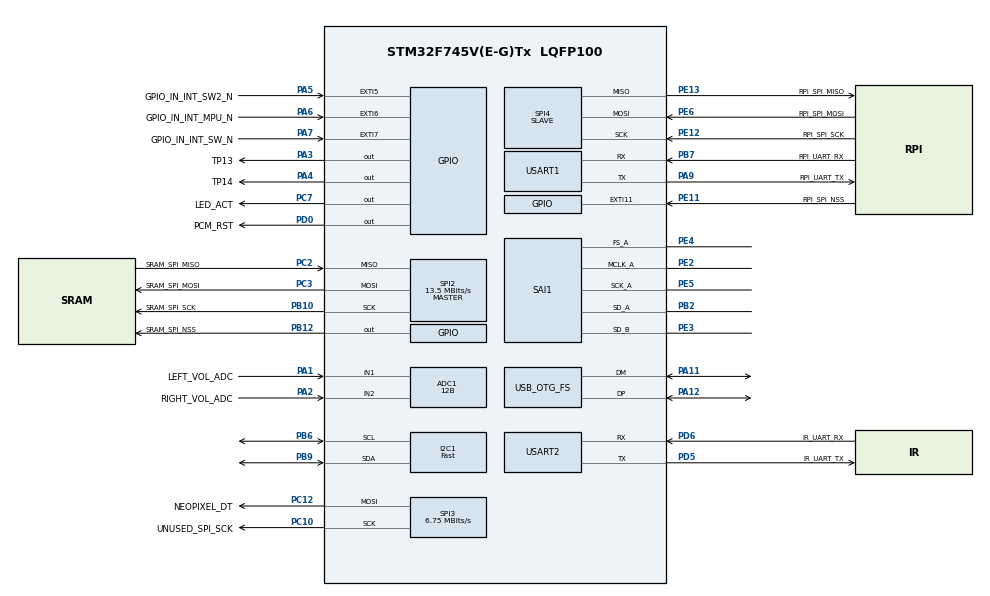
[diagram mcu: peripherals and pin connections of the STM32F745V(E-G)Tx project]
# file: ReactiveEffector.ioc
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ADC1.Channel-0\#ChannelRegularConversion=ADC_CHANNEL_1
ADC1.Channel-9\#ChannelRegularConversion=ADC_CHANNEL_2
ADC1.ClockPrescaler=ADC_CLOCK_SYNC_PCLK_DIV8
ADC1.ContinuousConvMode=ENABLE
ADC1.DMAContinuousRequests=ENABLE
ADC1.EOCSelection=ADC_EOC_SINGLE_CONV
ADC1.InjNumberOfConversion=0
ADC1.NbrOfConversion=2
ADC1.NbrOfConversionFlag=1
ADC1.Rank-0\#ChannelRegularConversion=1
ADC1.Rank-9\#ChannelRegularConversion=2
ADC1.Resolution=ADC_RESOLUTION_12B
ADC1.SamplingTime-0\#ChannelRegularConversion=ADC_SAMPLETIME_480CYCLES
ADC1.SamplingTime-9\#ChannelRegularConversion=ADC_SAMPLETIME_480CYCLES
ADC1.ScanConvMode=ADC_SCAN_ENABLE
ADC1.master=1
CORTEX_M7.ART_ACCLERATOR_ENABLE=0
CORTEX_M7.CPU_DCache=Enabled
CORTEX_M7.CPU_ICache=Enabled
CORTEX_M7.PREFETCH_ENABLE=0
CRC.InputDataFormat=CRC_INPUTDATA_FORMAT_WORDS
Dma.ADC1.11.Direction=DMA_PERIPH_TO_MEMORY
Dma.ADC1.11.FIFOMode=DMA_FIFOMODE_DISABLE
Dma.ADC1.11.Instance=DMA2_Stream4
Dma.ADC1.11.MemDataAlignment=DMA_MDATAALIGN_HALFWORD
Dma.ADC1.11.MemInc=DMA_MINC_ENABLE
Dma.ADC1.11.Mode=DMA_CIRCULAR
Dma.ADC1.11.PeriphDataAlignment=DMA_PDATAALIGN_HALFWORD
Dma.ADC1.11.PeriphInc=DMA_PINC_DISABLE
Dma.ADC1.11.Priority=DMA_PRIORITY_LOW
Dma.I2C1_RX.8.Direction=DMA_PERIPH_TO_MEMORY
Dma.I2C1_RX.8.FIFOMode=DMA_FIFOMODE_DISABLE
Dma.I2C1_RX.8.Instance=DMA1_Stream0
Dma.I2C1_RX.8.MemDataAlignment=DMA_MDATAALIGN_BYTE
Dma.I2C1_RX.8.MemInc=DMA_MINC_ENABLE
Dma.I2C1_RX.8.Mode=DMA_NORMAL
Dma.I2C1_RX.8.PeriphDataAlignment=DMA_PDATAALIGN_BYTE
Dma.I2C1_RX.8.PeriphInc=DMA_PINC_DISABLE
Dma.I2C1_RX.8.Priority=DMA_PRIORITY_LOW
Dma.I2C1_TX.5.Direction=DMA_MEMORY_TO_PERIPH
Dma.I2C1_TX.5.FIFOMode=DMA_FIFOMODE_DISABLE
Dma.I2C1_TX.5.Instance=DMA1_Stream7
Dma.I2C1_TX.5.MemDataAlignment=DMA_MDATAALIGN_BYTE
Dma.I2C1_TX.5.MemInc=DMA_MINC_ENABLE
Dma.I2C1_TX.5.Mode=DMA_NORMAL
Dma.I2C1_TX.5.PeriphDataAlignment=DMA_PDATAALIGN_BYTE
Dma.I2C1_TX.5.PeriphInc=DMA_PINC_DISABLE
Dma.I2C1_TX.5.Priority=DMA_PRIORITY_LOW
Dma.Request0=USART1_TX
Dma.Request1=SPI3_TX
Dma.Request10=SAI1_B
Dma.Request11=ADC1
Dma.Request2=USART2_TX
Dma.Request3=SPI4_RX
Dma.Request4=SPI4_TX
Dma.Request5=I2C1_TX
Dma.Request6=SPI2_RX
Dma.Request7=SPI2_TX
Dma.Request8=I2C1_RX
Dma.Request9=SAI1_A
Dma.SAI1_A.9.Direction=DMA_PERIPH_TO_MEMORY
Dma.SAI1_A.9.FIFOMode=DMA_FIFOMODE_DISABLE
Dma.SAI1_A.9.Instance=DMA2_Stream3
Dma.SAI1_A.9.MemDataAlignment=DMA_MDATAALIGN_WORD
Dma.SAI1_A.9.MemInc=DMA_MINC_ENABLE
Dma.SAI1_A.9.Mode=DMA_CIRCULAR
Dma.SAI1_A.9.PeriphDataAlignment=DMA_PDATAALIGN_WORD
Dma.SAI1_A.9.PeriphInc=DMA_PINC_DISABLE
Dma.SAI1_A.9.Priority=DMA_PRIORITY_LOW
Dma.SAI1_B.10.Direction=DMA_MEMORY_TO_PERIPH
Dma.SAI1_B.10.FIFOMode=DMA_FIFOMODE_DISABLE
Dma.SAI1_B.10.Instance=DMA2_Stream5
Dma.SAI1_B.10.MemDataAlignment=DMA_MDATAALIGN_WORD
Dma.SAI1_B.10.MemInc=DMA_MINC_ENABLE
Dma.SAI1_B.10.Mode=DMA_CIRCULAR
Dma.SAI1_B.10.PeriphDataAlignment=DMA_PDATAALIGN_WORD
Dma.SAI1_B.10.PeriphInc=DMA_PINC_DISABLE
Dma.SAI1_B.10.Priority=DMA_PRIORITY_LOW
Dma.SPI2_RX.6.Direction=DMA_PERIPH_TO_MEMORY
Dma.SPI2_RX.6.FIFOMode=DMA_FIFOMODE_DISABLE
Dma.SPI2_RX.6.Instance=DMA1_Stream3
Dma.SPI2_RX.6.MemDataAlignment=DMA_MDATAALIGN_BYTE
Dma.SPI2_RX.6.MemInc=DMA_MINC_ENABLE
Dma.SPI2_RX.6.Mode=DMA_NORMAL
Dma.SPI2_RX.6.PeriphDataAlignment=DMA_PDATAALIGN_BYTE
Dma.SPI2_RX.6.PeriphInc=DMA_PINC_DISABLE
Dma.SPI2_RX.6.Priority=DMA_PRIORITY_LOW
Dma.SPI2_TX.7.Direction=DMA_MEMORY_TO_PERIPH
Dma.SPI2_TX.7.FIFOMode=DMA_FIFOMODE_DISABLE
Dma.SPI2_TX.7.Instance=DMA1_Stream4
Dma.SPI2_TX.7.MemDataAlignment=DMA_MDATAALIGN_BYTE
Dma.SPI2_TX.7.MemInc=DMA_MINC_ENABLE
Dma.SPI2_TX.7.Mode=DMA_NORMAL
Dma.SPI2_TX.7.PeriphDataAlignment=DMA_PDATAALIGN_BYTE
Dma.SPI2_TX.7.PeriphInc=DMA_PINC_DISABLE
Dma.SPI2_TX.7.Priority=DMA_PRIORITY_LOW
Dma.SPI3_TX.1.Direction=DMA_MEMORY_TO_PERIPH
Dma.SPI3_TX.1.FIFOMode=DMA_FIFOMODE_DISABLE
Dma.SPI3_TX.1.Instance=DMA1_Stream5
Dma.SPI3_TX.1.MemDataAlignment=DMA_MDATAALIGN_HALFWORD
Dma.SPI3_TX.1.MemInc=DMA_MINC_ENABLE
Dma.SPI3_TX.1.Mode=DMA_NORMAL
Dma.SPI3_TX.1.PeriphDataAlignment=DMA_PDATAALIGN_HALFWORD
Dma.SPI3_TX.1.PeriphInc=DMA_PINC_DISABLE
Dma.SPI3_TX.1.Priority=DMA_PRIORITY_LOW
Dma.SPI4_RX.3.Direction=DMA_PERIPH_TO_MEMORY
Dma.SPI4_RX.3.FIFOMode=DMA_FIFOMODE_DISABLE
Dma.SPI4_RX.3.Instance=DMA2_Stream0
Dma.SPI4_RX.3.MemDataAlignment=DMA_MDATAALIGN_HALFWORD
Dma.SPI4_RX.3.MemInc=DMA_MINC_ENABLE
Dma.SPI4_RX.3.Mode=DMA_NORMAL
Dma.SPI4_RX.3.PeriphDataAlignment=DMA_PDATAALIGN_HALFWORD
Dma.SPI4_RX.3.PeriphInc=DMA_PINC_DISABLE
Dma.SPI4_RX.3.Priority=DMA_PRIORITY_LOW
Dma.SPI4_TX.4.Direction=DMA_MEMORY_TO_PERIPH
Dma.SPI4_TX.4.FIFOMode=DMA_FIFOMODE_DISABLE
Dma.SPI4_TX.4.Instance=DMA2_Stream1
Dma.SPI4_TX.4.MemDataAlignment=DMA_MDATAALIGN_HALFWORD
Dma.SPI4_TX.4.MemInc=DMA_MINC_ENABLE
Dma.SPI4_TX.4.Mode=DMA_NORMAL
Dma.SPI4_TX.4.PeriphDataAlignment=DMA_PDATAALIGN_HALFWORD
Dma.SPI4_TX.4.PeriphInc=DMA_PINC_DISABLE
Dma.SPI4_TX.4.Priority=DMA_PRIORITY_LOW
Dma.USART1_TX.0.Direction=DMA_MEMORY_TO_PERIPH
Dma.USART1_TX.0.FIFOMode=DMA_FIFOMODE_DISABLE
Dma.USART1_TX.0.Instance=DMA2_Stream7
Dma.USART1_TX.0.MemDataAlignment=DMA_MDATAALIGN_BYTE
Dma.USART1_TX.0.MemInc=DMA_MINC_ENABLE
Dma.USART1_TX.0.Mode=DMA_NORMAL
Dma.USART1_TX.0.PeriphDataAlignment=DMA_PDATAALIGN_BYTE
Dma.USART1_TX.0.PeriphInc=DMA_PINC_DISABLE
Dma.USART1_TX.0.Priority=DMA_PRIORITY_LOW
Dma.USART2_TX.2.Direction=DMA_MEMORY_TO_PERIPH
Dma.USART2_TX.2.FIFOMode=DMA_FIFOMODE_DISABLE
Dma.USART2_TX.2.Instance=DMA1_Stream6
Dma.USART2_TX.2.MemDataAlignment=DMA_MDATAALIGN_BYTE
Dma.USART2_TX.2.MemInc=DMA_MINC_ENABLE
Dma.USART2_TX.2.Mode=DMA_NORMAL
Dma.USART2_TX.2.PeriphDataAlignment=DMA_PDATAALIGN_BYTE
Dma.USART2_TX.2.PeriphInc=DMA_PINC_DISABLE
Dma.USART2_TX.2.Priority=DMA_PRIORITY_LOW
FREERTOS.HEAP_NUMBER=1
FREERTOS.Tasks01=usbTxTask,1,128,usbTxTaskProc,As weak,NULL,Dynamic,NULL,NULL;i2cTask,2,256,i2cTaskProc,As external,NULL,Dynamic,NULL,NULL;neoPixelTask,-3,128,neoPixelTaskProc,As external,NULL,Dynamic,NULL,NULL;appTask,-3,256,appTaskProc,As external,NULL,Dynamic,NULL,NULL;soundTask,3,256,soundTaskProc,As external,NULL,Dynamic,NULL,NULL;adcTask,-3,128,adcTaskProc,As external,NULL,Dynamic,NULL,NULL
FREERTOS.configENABLE_FPU=1
FREERTOS.configTOTAL_HEAP_SIZE=289000
FREERTOS.configUSE_NEWLIB_REENTRANT=1
FREERTOS.configUSE_TIMERS=0
I2C1.I2C_Fall_Time=50
I2C1.I2C_Rise_Time=50
I2C1.I2C_Speed_Mode=I2C_Fast
I2C1.Timing=0x00802F47
Mcu.Family=STM32F7
Mcu.Name=STM32F745V(E-G)Tx
Mcu.Package=LQFP100
Mcu.UserConstants=SRAM_SPI,SPI2;NP_SPI,SPI3;RPI_SPI,SPI4;RPI_UART,USART1;IR_UART,USART2
NVIC.DMA1_Stream0_IRQn=true\:5\:0\:false\:false\:false\:true\:false\:true\:true
NVIC.DMA1_Stream3_IRQn=true\:5\:0\:false\:false\:false\:true\:false\:true\:true
NVIC.DMA1_Stream4_IRQn=true\:5\:0\:false\:false\:false\:true\:false\:true\:true
NVIC.DMA1_Stream5_IRQn=true\:5\:0\:false\:false\:false\:true\:false\:true\:true
NVIC.DMA1_Stream6_IRQn=true\:5\:0\:false\:false\:false\:true\:false\:true\:true
NVIC.DMA1_Stream7_IRQn=true\:5\:0\:false\:false\:false\:true\:false\:true\:true
NVIC.DMA2_Stream0_IRQn=true\:5\:0\:false\:false\:false\:true\:false\:true\:true
NVIC.DMA2_Stream1_IRQn=true\:5\:0\:false\:false\:false\:true\:false\:true\:true
NVIC.DMA2_Stream3_IRQn=true\:5\:0\:false\:false\:false\:true\:false\:true\:true
NVIC.DMA2_Stream4_IRQn=true\:5\:0\:false\:false\:false\:true\:false\:true\:true
NVIC.DMA2_Stream5_IRQn=true\:5\:0\:false\:false\:false\:true\:false\:true\:true
NVIC.DMA2_Stream7_IRQn=true\:5\:0\:false\:false\:false\:true\:false\:true\:true
NVIC.EXTI15_10_IRQn=true\:5\:0\:false\:false\:false\:true\:true\:true\:true
NVIC.EXTI9_5_IRQn=true\:5\:0\:false\:false\:false\:true\:true\:true\:true
NVIC.I2C1_ER_IRQn=true\:5\:0\:false\:false\:false\:true\:true\:true\:true
NVIC.I2C1_EV_IRQn=true\:5\:0\:false\:false\:false\:true\:true\:true\:true
NVIC.OTG_FS_IRQn=true\:5\:0\:false\:false\:false\:true\:false\:true\:true
NVIC.PriorityGroup=NVIC_PRIORITYGROUP_4
NVIC.TIM1_UP_TIM10_IRQn=true\:5\:0\:false\:false\:false\:true\:true\:true\:true
NVIC.TIM6_DAC_IRQn=true\:5\:0\:false\:false\:false\:true\:true\:true\:true
NVIC.TIM7_IRQn=true\:0\:0\:false\:false\:false\:false\:false\:true\:true
NVIC.TimeBase=TIM7_IRQn
NVIC.TimeBaseIP=TIM7
NVIC.USART1_IRQn=true\:5\:0\:false\:false\:false\:true\:true\:true\:true
NVIC.USART2_IRQn=true\:5\:0\:false\:false\:false\:true\:true\:true\:true
PA1.GPIO_Label=LEFT_VOL_ADC
PA1.Signal=ADCx_IN1
PA10.Signal=USB_OTG_FS_ID
PA11.Mode=Device_Only
PA11.Signal=USB_OTG_FS_DM
PA12.Mode=Device_Only
PA12.Signal=USB_OTG_FS_DP
PA13.Mode=JTAG_5_pins
PA13.Signal=SYS_JTMS-SWDIO
PA14.Mode=JTAG_5_pins
PA14.Signal=SYS_JTCK-SWCLK
PA15.Mode=JTAG_5_pins
PA15.Signal=SYS_JTDI
PA2.GPIO_Label=RIGHT_VOL_ADC
PA2.Signal=ADCx_IN2
PA3.GPIO_Label=TP13
PA3.Signal=GPIO_Output
PA4.GPIO_Label=TP14
PA4.Signal=GPIO_Output
PA5.GPIO_Label=GPIO_IN_INT_SW2_N
PA5.GPIO_ModeDefaultEXTI=GPIO_MODE_IT_FALLING
PA5.GPIO_PuPd=GPIO_PULLUP
PA5.Signal=GPXTI5
PA6.GPIO_Label=GPIO_IN_INT_MPU_N
PA6.GPIO_ModeDefaultEXTI=GPIO_MODE_IT_FALLING
PA6.GPIO_PuPd=GPIO_PULLUP
PA6.Signal=GPXTI6
PA7.GPIO_Label=GPIO_IN_INT_SW_N
PA7.GPIO_ModeDefaultEXTI=GPIO_MODE_IT_FALLING
PA7.GPIO_PuPd=GPIO_PULLUP
PA7.Signal=GPXTI7
PA9.GPIO_Label=RPI_UART_TX
PA9.Mode=Asynchronous
PA9.Signal=USART1_TX
PB10.GPIO_Label=SRAM_SPI_SCK
PB10.Mode=Full_Duplex_Master
PB10.Signal=SPI2_SCK
PB12.GPIO_Label=SRAM_SPI_NSS
PB12.Signal=GPIO_Output
PB2.Mode=SAI_A_MasterWithClock
PB2.Signal=SAI1_SD_A
PB3.Mode=JTAG_5_pins
PB3.Signal=SYS_JTDO-SWO
PB4.Mode=JTAG_5_pins
PB4.Signal=SYS_JTRST
PB6.GPIO_Pu=GPIO_PULLUP
PB6.Mode=I2C
PB6.Signal=I2C1_SCL
PB7.GPIO_Label=RPI_UART_RX
PB7.Mode=Asynchronous
PB7.Signal=USART1_RX
PB9.GPIO_Pu=GPIO_PULLUP
PB9.Mode=I2C
PB9.Signal=I2C1_SDA
PC1.Mode=SYS_WakeUp2
PC1.Signal=SYS_WKUP3
PC10.GPIO_Label=UNUSED_SPI_SCK
PC10.Mode=TX_Only_Simplex_Unidirect_Master
PC10.Signal=SPI3_SCK
PC12.GPIO_Label=NEOPIXEL_DT
PC12.Mode=TX_Only_Simplex_Unidirect_Master
PC12.Signal=SPI3_MOSI
PC2.GPIO_Label=SRAM_SPI_MISO
PC2.Mode=Full_Duplex_Master
PC2.Signal=SPI2_MISO
PC3.GPIO_Label=SRAM_SPI_MOSI
PC3.Mode=Full_Duplex_Master
PC3.Signal=SPI2_MOSI
PC7.GPIO_Label=LED_ACT
PC7.Signal=GPIO_Output
PD0.GPIO_Label=PCM_RST
PD0.Signal=GPIO_Output
PD5.GPIO_Label=IR_UART_TX
PD5.Mode=Asynchronous
PD5.Signal=USART2_TX
PD6.GPIO_Label=IR_UART_RX
PD6.Mode=Asynchronous
PD6.Signal=USART2_RX
PE11.GPIO_Label=RPI_SPI_NSS
PE11.GPIO_ModeDefaultEXTI=GPIO_MODE_IT_FALLING
PE11.Signal=GPXTI11
PE12.GPIO_Label=RPI_SPI_SCK
PE12.Mode=Full_Duplex_Slave
PE12.Signal=SPI4_SCK
PE13.GPIO_Label=RPI_SPI_MISO
PE13.Mode=Full_Duplex_Slave
PE13.Signal=SPI4_MISO
PE2.Mode=SAI_A_MasterWithClock
PE2.Signal=SAI1_MCLK_A
PE3.Mode=SAI_B_SyncSlave
PE3.Signal=SAI1_SD_B
PE4.Mode=SAI_A_MasterWithClock
PE4.Signal=SAI1_FS_A
PE5.Mode=SAI_A_MasterWithClock
PE5.Signal=SAI1_SCK_A
PE6.GPIO_Label=RPI_SPI_MOSI
PE6.Mode=Full_Duplex_Slave
PE6.Signal=SPI4_MOSI
PH0/OSC_IN.Mode=HSE-External-Oscillator
PH0/OSC_IN.Signal=RCC_OSC_IN
PH1/OSC_OUT.Mode=HSE-External-Oscillator
PH1/OSC_OUT.Signal=RCC_OSC_OUT
ProjectManager.HeapSize=0x200
ProjectManager.StackSize=0x1000
ProjectManager.TargetToolchain=STM32CubeIDE
RCC.AHBFreq_Value=216000000
RCC.APB1CLKDivider=RCC_HCLK_DIV4
RCC.APB1Freq_Value=54000000
RCC.APB1TimFreq_Value=108000000
RCC.APB2CLKDivider=RCC_HCLK_DIV2
RCC.APB2Freq_Value=108000000
RCC.APB2TimFreq_Value=216000000
RCC.CortexFreq_Value=216000000
RCC.HCLKFreq_Value=216000000
RCC.HSE_VALUE=8000000
RCC.HSI_VALUE=16000000
RCC.LSE_VALUE=32768
RCC.PLLI2SN=216
RCC.PLLM=4
RCC.PLLN=216
RCC.PLLQ=9
RCC.PLLSAIN=182
RCC.SYSCLKFreq_VALUE=216000000
RCC.SYSCLKSource=RCC_SYSCLKSOURCE_PLLCLK
RCC.USBFreq_Value=48000000
RCC.VCOOutputFreq_Value=432000000
SAI1.AudioFrequency-SAI_A_MasterWithClock=SAI_AUDIO_FREQUENCY_44K
SAI1.AudioMode-SAI_A_MasterWithClock=SAI_MODEMASTER_RX
SAI1.AudioMode-SAI_B_SyncSlave=SAI_MODESLAVE_TX
SAI1.BasicDataSize-SAI_A_MasterWithClock=SAI_PROTOCOL_DATASIZE_32BIT
SAI1.BasicDataSize-SAI_B_SyncSlave=SAI_PROTOCOL_DATASIZE_32BIT
SAI1.ErrorAudioFreq-SAI_A_MasterWithClock=0.98 %
SAI1.FIFOThreshold-SAI_B_SyncSlave=SAI_FIFOTHRESHOLD_HF
SAI1.InitProtocol-SAI_A_MasterWithClock=Enable
SAI1.InitProtocol-SAI_B_SyncSlave=Enable
SAI1.Instance-SAI_A_MasterWithClock=SAI$Index_Block_A
SAI1.Instance-SAI_B_SyncSlave=SAI$Index_Block_B
SAI1.MClockEnable=SAI_MASTERCLOCK_ENABLE
SAI1.RealAudioFreq-SAI_A_MasterWithClock=44.433 KHz
SAI1.VirtualMode-SAI_A_MasterWithClock=VM_MASTER
SAI1.VirtualMode-SAI_B_SyncSlave=VM_SLAVE
SAI1.VirtualProtocol-SAI_A_BASIC=VM_BASIC_PROTOCOL
SAI1.VirtualProtocol-SAI_B_BASIC=VM_BASIC_PROTOCOL
SH.ADCx_IN1.0=ADC1_IN1,IN1
SH.ADCx_IN2.0=ADC1_IN2,IN2
SPI2.BaudRatePrescaler=SPI_BAUDRATEPRESCALER_4
SPI2.CLKPhase=SPI_PHASE_2EDGE
SPI2.CLKPolarity=SPI_POLARITY_HIGH
SPI2.CalculateBaudRate=13.5 MBits/s
SPI2.DataSize=SPI_DATASIZE_8BIT
SPI2.Direction=SPI_DIRECTION_2LINES
SPI2.Mode=SPI_MODE_MASTER
SPI2.VirtualType=VM_MASTER
SPI3.BaudRatePrescaler=SPI_BAUDRATEPRESCALER_8
SPI3.CLKPhase=SPI_PHASE_2EDGE
SPI3.CLKPolarity=SPI_POLARITY_HIGH
SPI3.CalculateBaudRate=6.75 MBits/s
SPI3.DataSize=SPI_DATASIZE_8BIT
SPI3.Direction=SPI_DIRECTION_2LINES
SPI3.Mode=SPI_MODE_MASTER
SPI3.VirtualType=VM_MASTER
SPI4.CLKPhase=SPI_PHASE_2EDGE
SPI4.DataSize=SPI_DATASIZE_8BIT
SPI4.Direction=SPI_DIRECTION_2LINES
SPI4.Mode=SPI_MODE_SLAVE
SPI4.VirtualType=VM_SLAVE
TIM10.ClockDivision=TIM_CLOCKDIVISION_DIV2
TIM10.Period=999
TIM10.Prescaler=10799
TIM6.Period=4999
TIM6.Prescaler=10799
USART1.VirtualMode-Asynchronous=VM_ASYNC
USART2.VirtualMode-Asynchronous=VM_ASYNC
USB_DEVICE.CLASS_NAME_FS=CDC
USB_DEVICE.MANUFACTURER_STRING-CDC_FS=SATOH GADGET
USB_DEVICE.PRODUCT_STRING_CDC_FS=ReactiveEffector RE-1
USB_DEVICE.VirtualMode-CDC_FS=Cdc
USB_DEVICE.VirtualModeFS=Cdc_FS
USB_OTG_FS.VirtualMode=Device_Only
VP_CRC_VS_CRC.Mode=CRC_Activate
VP_FREERTOS_VS_CMSIS_V1.Mode=CMSIS_V1
VP_SAI1_VP_$IpInstance_SAIA_SAI_BASIC.Mode=SAI_A_BASIC
VP_SAI1_VP_$IpInstance_SAIB_SAI_BASIC.Mode=SAI_B_BASIC
VP_SYS_VS_tim7.Mode=TIM7
VP_TIM10_VS_ClockSourceINT.Mode=Enable_Timer
VP_TIM6_VS_ClockSourceINT.Mode=Enable_Timer
VP_USB_DEVICE_VS_USB_DEVICE_CDC_FS.Mode=CDC_FS
board=custom

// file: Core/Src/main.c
/* USER CODE BEGIN Header */
/**
  ******************************************************************************
  * @file           : main.c
  * @brief          : Main program body
  ******************************************************************************
  * @attention
  *
  * <h2><center>&copy; Copyright (c) 2021 STMicroelectronics.
  * All rights reserved.</center></h2>
  *
  * This software component is licensed by ST under BSD 3-Clause license,
  * the "License"; You may not use this file except in compliance with the
  * License. You may obtain a copy of the License at:
  *                        opensource.org/licenses/BSD-3-Clause
  *
  ******************************************************************************
  */
/* USER CODE END Header */
#include "main.h"
#include "cmsis_os.h"
#include "usb_device.h"

SAI_HandleTypeDef hsai_BlockA1;
SAI_HandleTypeDef hsai_BlockB1;
DMA_HandleTypeDef hdma_sai1_a;
DMA_HandleTypeDef hdma_sai1_b;

osThreadId usbTxTaskHandle;
osThreadId i2cTaskHandle;
osThreadId neoPixelTaskHandle;
osThreadId appTaskHandle;
osThreadId soundTaskHandle;
osThreadId adcTaskHandle;
osThreadId i2cMonitorTaskHandle;

void SystemClock_Config(void);
void PeriphCommonClock_Config(void);
static void MX_GPIO_Init(void);
static void MX_DMA_Init(void);
static void MX_USART1_UART_Init(void);
static void MX_SPI3_Init(void);
static void MX_ADC1_Init(void);
static void MX_USART2_UART_Init(void);
static void MX_SPI4_Init(void);
static void MX_I2C1_Init(void);
static void MX_SPI2_Init(void);
static void MX_SAI1_Init(void);
static void MX_TIM6_Init(void);
static void MX_TIM10_Init(void);
static void MX_CRC_Init(void);
void usbTxTaskProc(void const * argument);
extern void i2cTaskProc(void const * argument);
extern void neoPixelTaskProc(void const * argument);
extern void appTaskProc(void const * argument);
extern void soundTaskProc(void const * argument);
extern void adcTaskProc(void const * argument);
extern void i2cMonitorTaskProc(void const * argument);

int main(void)
{

  /* Enable I-Cache---------------------------------------------------------*/
  SCB_EnableICache();

  /* Enable D-Cache---------------------------------------------------------*/
  SCB_EnableDCache();

  /* MCU Configuration--------------------------------------------------------*/

  /* Reset of all peripherals, Initializes the Flash interface and the Systick. */
  HAL_Init();

  /* Configure the system clock */
  SystemClock_Config();

/* Configure the peripherals common clocks */
  PeriphCommonClock_Config();

  /* Initialize all configured peripherals */
  MX_GPIO_Init();
  MX_DMA_Init();
  MX_USART1_UART_Init();
  MX_SPI3_Init();
  MX_ADC1_Init();
  MX_USART2_UART_Init();
  MX_SPI4_Init();
  MX_I2C1_Init();
  MX_SPI2_Init();
  MX_SAI1_Init();
  MX_TIM6_Init();
  MX_TIM10_Init();
  MX_CRC_Init();

  /* Create the thread(s) */
  /* definition and creation of usbTxTask */
  osThreadDef(usbTxTask, usbTxTaskProc, osPriorityAboveNormal, 0, 128);
  usbTxTaskHandle = osThreadCreate(osThread(usbTxTask), NULL);

  /* definition and creation of i2cTask */
  osThreadDef(i2cTask, i2cTaskProc, osPriorityHigh, 0, 256);
  i2cTaskHandle = osThreadCreate(osThread(i2cTask), NULL);

  /* definition and creation of neoPixelTask */
  osThreadDef(neoPixelTask, neoPixelTaskProc, osPriorityIdle, 0, 128);
  neoPixelTaskHandle = osThreadCreate(osThread(neoPixelTask), NULL);

  /* definition and creation of appTask */
  osThreadDef(appTask, appTaskProc, osPriorityIdle, 0, 256);
  appTaskHandle = osThreadCreate(osThread(appTask), NULL);

  /* definition and creation of soundTask */
  osThreadDef(soundTask, soundTaskProc, osPriorityRealtime, 0, 256);
  soundTaskHandle = osThreadCreate(osThread(soundTask), NULL);

  /* definition and creation of adcTask */
  osThreadDef(adcTask, adcTaskProc, osPriorityIdle, 0, 128);
  adcTaskHandle = osThreadCreate(osThread(adcTask), NULL);

  /* definition and creation of i2cMonitorTask */
  osThreadDef(i2cMonitorTask, i2cMonitorTaskProc, osPriorityIdle, 0, 128);
  i2cMonitorTaskHandle = osThreadCreate(osThread(i2cMonitorTask), NULL);

  /* USER CODE BEGIN RTOS_THREADS */
  /* add threads, ... */
  LL_TIM_EnableCounter(TIM10);
  LL_TIM_EnableIT_UPDATE(TIM10);
  /* USER CODE END RTOS_THREADS */

  /* Start scheduler */
  osKernelStart();

  /* We should never get here as control is now taken by the scheduler */
  /* Infinite loop */
  while (1)
  {

  }
}

void SystemClock_Config(void)
{
  LL_FLASH_SetLatency(LL_FLASH_LATENCY_7);
  while(LL_FLASH_GetLatency()!= LL_FLASH_LATENCY_7)
  {
  }
  LL_PWR_SetRegulVoltageScaling(LL_PWR_REGU_VOLTAGE_SCALE1);
  LL_PWR_EnableOverDriveMode();
  LL_RCC_HSE_Enable();

   /* Wait till HSE is ready */
  while(LL_RCC_HSE_IsReady() != 1)
  {

  }
  LL_RCC_PLL_ConfigDomain_SYS(LL_RCC_PLLSOURCE_HSE, LL_RCC_PLLM_DIV_4, 216, LL_RCC_PLLP_DIV_2);
  LL_RCC_PLL_ConfigDomain_48M(LL_RCC_PLLSOURCE_HSE, LL_RCC_PLLM_DIV_4, 216, LL_RCC_PLLQ_DIV_9);
  LL_RCC_PLL_Enable();

   /* Wait till PLL is ready */
  while(LL_RCC_PLL_IsReady() != 1)
  {

  }
  LL_RCC_SetAHBPrescaler(LL_RCC_SYSCLK_DIV_1);
  LL_RCC_SetAPB1Prescaler(LL_RCC_APB1_DIV_4);
  LL_RCC_SetAPB2Prescaler(LL_RCC_APB2_DIV_2);
  LL_RCC_SetSysClkSource(LL_RCC_SYS_CLKSOURCE_PLL);

   /* Wait till System clock is ready */
  while(LL_RCC_GetSysClkSource() != LL_RCC_SYS_CLKSOURCE_STATUS_PLL)
  {

  }
  LL_SetSystemCoreClock(216000000);

   /* Update the time base */
  if (HAL_InitTick (TICK_INT_PRIORITY) != HAL_OK)
  {
    Error_Handler();
  }
}

void PeriphCommonClock_Config(void)
{
  LL_RCC_PLLSAI_ConfigDomain_SAI(LL_RCC_PLLSOURCE_HSE, LL_RCC_PLLM_DIV_4, 182, LL_RCC_PLLSAIQ_DIV_2, LL_RCC_PLLSAIDIVQ_DIV_1);
  LL_RCC_PLLSAI_Enable();

   /* Wait till PLL is ready */
  while(LL_RCC_PLLSAI_IsReady() != 1)
  {

  }
}

static void MX_ADC1_Init(void)
{

  LL_ADC_InitTypeDef ADC_InitStruct = {0};
  LL_ADC_REG_InitTypeDef ADC_REG_InitStruct = {0};
  LL_ADC_CommonInitTypeDef ADC_CommonInitStruct = {0};

  LL_GPIO_InitTypeDef GPIO_InitStruct = {0};

  /* Peripheral clock enable */
  LL_APB2_GRP1_EnableClock(LL_APB2_GRP1_PERIPH_ADC1);

  LL_AHB1_GRP1_EnableClock(LL_AHB1_GRP1_PERIPH_GPIOA);
  /**ADC1 GPIO Configuration
  PA1   ------> ADC1_IN1
  PA2   ------> ADC1_IN2
  */
  GPIO_InitStruct.Pin = LEFT_VOL_ADC_Pin;
  GPIO_InitStruct.Mode = LL_GPIO_MODE_ANALOG;
  GPIO_InitStruct.Pull = LL_GPIO_PULL_NO;
  LL_GPIO_Init(LEFT_VOL_ADC_GPIO_Port, &GPIO_InitStruct);

  GPIO_InitStruct.Pin = RIGHT_VOL_ADC_Pin;
  GPIO_InitStruct.Mode = LL_GPIO_MODE_ANALOG;
  GPIO_InitStruct.Pull = LL_GPIO_PULL_NO;
  LL_GPIO_Init(RIGHT_VOL_ADC_GPIO_Port, &GPIO_InitStruct);

  /* ADC1 DMA Init */

  /* ADC1 Init */
  LL_DMA_SetChannelSelection(DMA2, LL_DMA_STREAM_4, LL_DMA_CHANNEL_0);

  LL_DMA_SetDataTransferDirection(DMA2, LL_DMA_STREAM_4, LL_DMA_DIRECTION_PERIPH_TO_MEMORY);

  LL_DMA_SetStreamPriorityLevel(DMA2, LL_DMA_STREAM_4, LL_DMA_PRIORITY_LOW);

  LL_DMA_SetMode(DMA2, LL_DMA_STREAM_4, LL_DMA_MODE_CIRCULAR);

  LL_DMA_SetPeriphIncMode(DMA2, LL_DMA_STREAM_4, LL_DMA_PERIPH_NOINCREMENT);

  LL_DMA_SetMemoryIncMode(DMA2, LL_DMA_STREAM_4, LL_DMA_MEMORY_INCREMENT);

  LL_DMA_SetPeriphSize(DMA2, LL_DMA_STREAM_4, LL_DMA_PDATAALIGN_HALFWORD);

  LL_DMA_SetMemorySize(DMA2, LL_DMA_STREAM_4, LL_DMA_MDATAALIGN_HALFWORD);

  LL_DMA_DisableFifoMode(DMA2, LL_DMA_STREAM_4);

  /** Common config
  */
  ADC_InitStruct.Resolution = LL_ADC_RESOLUTION_12B;
  ADC_InitStruct.DataAlignment = LL_ADC_DATA_ALIGN_RIGHT;
  ADC_InitStruct.SequencersScanMode = LL_ADC_SEQ_SCAN_ENABLE;
  LL_ADC_Init(ADC1, &ADC_InitStruct);
  ADC_REG_InitStruct.TriggerSource = LL_ADC_REG_TRIG_SOFTWARE;
  ADC_REG_InitStruct.SequencerLength = LL_ADC_REG_SEQ_SCAN_ENABLE_2RANKS;
  ADC_REG_InitStruct.SequencerDiscont = LL_ADC_REG_SEQ_DISCONT_DISABLE;
  ADC_REG_InitStruct.ContinuousMode = LL_ADC_REG_CONV_CONTINUOUS;
  ADC_REG_InitStruct.DMATransfer = LL_ADC_REG_DMA_TRANSFER_UNLIMITED;
  LL_ADC_REG_Init(ADC1, &ADC_REG_InitStruct);
  LL_ADC_REG_SetFlagEndOfConversion(ADC1, LL_ADC_REG_FLAG_EOC_UNITARY_CONV);
  ADC_CommonInitStruct.CommonClock = LL_ADC_CLOCK_SYNC_PCLK_DIV8;
  ADC_CommonInitStruct.Multimode = LL_ADC_MULTI_INDEPENDENT;
  LL_ADC_CommonInit(__LL_ADC_COMMON_INSTANCE(ADC1), &ADC_CommonInitStruct);
  /** Configure Regular Channel
  */
  LL_ADC_REG_SetSequencerRanks(ADC1, LL_ADC_REG_RANK_1, LL_ADC_CHANNEL_1);
  LL_ADC_SetChannelSamplingTime(ADC1, LL_ADC_CHANNEL_1, LL_ADC_SAMPLINGTIME_480CYCLES);
  /** Configure Regular Channel
  */
  LL_ADC_REG_SetSequencerRanks(ADC1, LL_ADC_REG_RANK_2, LL_ADC_CHANNEL_2);
  LL_ADC_SetChannelSamplingTime(ADC1, LL_ADC_CHANNEL_2, LL_ADC_SAMPLINGTIME_480CYCLES);

}

static void MX_CRC_Init(void)
{

  /* Peripheral clock enable */
  LL_AHB1_GRP1_EnableClock(LL_AHB1_GRP1_PERIPH_CRC);

  LL_CRC_SetInputDataReverseMode(CRC, LL_CRC_INDATA_REVERSE_NONE);
  LL_CRC_SetOutputDataReverseMode(CRC, LL_CRC_OUTDATA_REVERSE_NONE);
  LL_CRC_SetPolynomialCoef(CRC, LL_CRC_DEFAULT_CRC32_POLY);
  LL_CRC_SetPolynomialSize(CRC, LL_CRC_POLYLENGTH_32B);
  LL_CRC_SetInitialData(CRC, LL_CRC_DEFAULT_CRC_INITVALUE);

}

static void MX_I2C1_Init(void)
{

  LL_I2C_InitTypeDef I2C_InitStruct = {0};

  LL_GPIO_InitTypeDef GPIO_InitStruct = {0};

  LL_RCC_SetI2CClockSource(LL_RCC_I2C1_CLKSOURCE_PCLK1);

  LL_AHB1_GRP1_EnableClock(LL_AHB1_GRP1_PERIPH_GPIOB);
  /**I2C1 GPIO Configuration
  PB6   ------> I2C1_SCL
  PB9   ------> I2C1_SDA
  */
  GPIO_InitStruct.Pin = LL_GPIO_PIN_6;
  GPIO_InitStruct.Mode = LL_GPIO_MODE_ALTERNATE;
  GPIO_InitStruct.Speed = LL_GPIO_SPEED_FREQ_VERY_HIGH;
  GPIO_InitStruct.OutputType = LL_GPIO_OUTPUT_OPENDRAIN;
  GPIO_InitStruct.Pull = LL_GPIO_PULL_UP;
  GPIO_InitStruct.Alternate = LL_GPIO_AF_4;
  LL_GPIO_Init(GPIOB, &GPIO_InitStruct);

  GPIO_InitStruct.Pin = LL_GPIO_PIN_9;
  GPIO_InitStruct.Mode = LL_GPIO_MODE_ALTERNATE;
  GPIO_InitStruct.Speed = LL_GPIO_SPEED_FREQ_VERY_HIGH;
  GPIO_InitStruct.OutputType = LL_GPIO_OUTPUT_OPENDRAIN;
  GPIO_InitStruct.Pull = LL_GPIO_PULL_UP;
  GPIO_InitStruct.Alternate = LL_GPIO_AF_4;
  LL_GPIO_Init(GPIOB, &GPIO_InitStruct);

  /* Peripheral clock enable */
  LL_APB1_GRP1_EnableClock(LL_APB1_GRP1_PERIPH_I2C1);

  /* I2C1 DMA Init */

  /* I2C1_TX Init */
  LL_DMA_SetChannelSelection(DMA1, LL_DMA_STREAM_7, LL_DMA_CHANNEL_1);

  LL_DMA_SetDataTransferDirection(DMA1, LL_DMA_STREAM_7, LL_DMA_DIRECTION_MEMORY_TO_PERIPH);

  LL_DMA_SetStreamPriorityLevel(DMA1, LL_DMA_STREAM_7, LL_DMA_PRIORITY_LOW);

  LL_DMA_SetMode(DMA1, LL_DMA_STREAM_7, LL_DMA_MODE_NORMAL);

  LL_DMA_SetPeriphIncMode(DMA1, LL_DMA_STREAM_7, LL_DMA_PERIPH_NOINCREMENT);

  LL_DMA_SetMemoryIncMode(DMA1, LL_DMA_STREAM_7, LL_DMA_MEMORY_INCREMENT);

  LL_DMA_SetPeriphSize(DMA1, LL_DMA_STREAM_7, LL_DMA_PDATAALIGN_BYTE);

  LL_DMA_SetMemorySize(DMA1, LL_DMA_STREAM_7, LL_DMA_MDATAALIGN_BYTE);

  LL_DMA_DisableFifoMode(DMA1, LL_DMA_STREAM_7);

  /* I2C1_RX Init */
  LL_DMA_SetChannelSelection(DMA1, LL_DMA_STREAM_0, LL_DMA_CHANNEL_1);

  LL_DMA_SetDataTransferDirection(DMA1, LL_DMA_STREAM_0, LL_DMA_DIRECTION_PERIPH_TO_MEMORY);

  LL_DMA_SetStreamPriorityLevel(DMA1, LL_DMA_STREAM_0, LL_DMA_PRIORITY_LOW);

  LL_DMA_SetMode(DMA1, LL_DMA_STREAM_0, LL_DMA_MODE_NORMAL);

  LL_DMA_SetPeriphIncMode(DMA1, LL_DMA_STREAM_0, LL_DMA_PERIPH_NOINCREMENT);

  LL_DMA_SetMemoryIncMode(DMA1, LL_DMA_STREAM_0, LL_DMA_MEMORY_INCREMENT);

  LL_DMA_SetPeriphSize(DMA1, LL_DMA_STREAM_0, LL_DMA_PDATAALIGN_BYTE);

  LL_DMA_SetMemorySize(DMA1, LL_DMA_STREAM_0, LL_DMA_MDATAALIGN_BYTE);

  LL_DMA_DisableFifoMode(DMA1, LL_DMA_STREAM_0);

  /* I2C1 interrupt Init */
  NVIC_SetPriority(I2C1_EV_IRQn, NVIC_EncodePriority(NVIC_GetPriorityGrouping(),5, 0));
  NVIC_EnableIRQ(I2C1_EV_IRQn);
  NVIC_SetPriority(I2C1_ER_IRQn, NVIC_EncodePriority(NVIC_GetPriorityGrouping(),5, 0));
  NVIC_EnableIRQ(I2C1_ER_IRQn);

  /** I2C Initialization
  */
  LL_I2C_EnableAutoEndMode(I2C1);
  LL_I2C_SetOwnAddress2(I2C1, 0, LL_I2C_OWNADDRESS2_NOMASK);
  LL_I2C_DisableOwnAddress2(I2C1);
  LL_I2C_DisableGeneralCall(I2C1);
  LL_I2C_EnableClockStretching(I2C1);
  I2C_InitStruct.PeripheralMode = LL_I2C_MODE_I2C;
  I2C_InitStruct.Timing = 0x00802F47;
  I2C_InitStruct.AnalogFilter = LL_I2C_ANALOGFILTER_ENABLE;
  I2C_InitStruct.DigitalFilter = 0;
  I2C_InitStruct.OwnAddress1 = 0;
  I2C_InitStruct.TypeAcknowledge = LL_I2C_ACK;
  I2C_InitStruct.OwnAddrSize = LL_I2C_OWNADDRESS1_7BIT;
  LL_I2C_Init(I2C1, &I2C_InitStruct);

}

static void MX_SAI1_Init(void)
{

  hsai_BlockA1.Instance = SAI1_Block_A;
  hsai_BlockA1.Init.AudioMode = SAI_MODEMASTER_RX;
  hsai_BlockA1.Init.Synchro = SAI_ASYNCHRONOUS;
  hsai_BlockA1.Init.OutputDrive = SAI_OUTPUTDRIVE_DISABLE;
  hsai_BlockA1.Init.NoDivider = SAI_MASTERDIVIDER_ENABLE;
  hsai_BlockA1.Init.FIFOThreshold = SAI_FIFOTHRESHOLD_EMPTY;
  hsai_BlockA1.Init.AudioFrequency = SAI_AUDIO_FREQUENCY_44K;
  hsai_BlockA1.Init.SynchroExt = SAI_SYNCEXT_DISABLE;
  hsai_BlockA1.Init.MonoStereoMode = SAI_STEREOMODE;
  hsai_BlockA1.Init.CompandingMode = SAI_NOCOMPANDING;
  if (HAL_SAI_InitProtocol(&hsai_BlockA1, SAI_I2S_STANDARD, SAI_PROTOCOL_DATASIZE_32BIT, 2) != HAL_OK)
  {
    Error_Handler();
  }
  hsai_BlockB1.Instance = SAI1_Block_B;
  hsai_BlockB1.Init.AudioMode = SAI_MODESLAVE_TX;
  hsai_BlockB1.Init.Synchro = SAI_SYNCHRONOUS;
  hsai_BlockB1.Init.OutputDrive = SAI_OUTPUTDRIVE_DISABLE;
  hsai_BlockB1.Init.FIFOThreshold = SAI_FIFOTHRESHOLD_HF;
  hsai_BlockB1.Init.SynchroExt = SAI_SYNCEXT_DISABLE;
  hsai_BlockB1.Init.MonoStereoMode = SAI_STEREOMODE;
  hsai_BlockB1.Init.CompandingMode = SAI_NOCOMPANDING;
  hsai_BlockB1.Init.TriState = SAI_OUTPUT_NOTRELEASED;
  if (HAL_SAI_InitProtocol(&hsai_BlockB1, SAI_I2S_STANDARD, SAI_PROTOCOL_DATASIZE_32BIT, 2) != HAL_OK)
  {
    Error_Handler();
  }

}

static void MX_SPI2_Init(void)
{

  LL_SPI_InitTypeDef SPI_InitStruct = {0};

  LL_GPIO_InitTypeDef GPIO_InitStruct = {0};

  /* Peripheral clock enable */
  LL_APB1_GRP1_EnableClock(LL_APB1_GRP1_PERIPH_SPI2);

  LL_AHB1_GRP1_EnableClock(LL_AHB1_GRP1_PERIPH_GPIOC);
  LL_AHB1_GRP1_EnableClock(LL_AHB1_GRP1_PERIPH_GPIOB);
  /**SPI2 GPIO Configuration
  PC2   ------> SPI2_MISO
  PC3   ------> SPI2_MOSI
  PB10   ------> SPI2_SCK
  */
  GPIO_InitStruct.Pin = SRAM_SPI_MISO_Pin;
  GPIO_InitStruct.Mode = LL_GPIO_MODE_ALTERNATE;
  GPIO_InitStruct.Speed = LL_GPIO_SPEED_FREQ_VERY_HIGH;
  GPIO_InitStruct.OutputType = LL_GPIO_OUTPUT_PUSHPULL;
  GPIO_InitStruct.Pull = LL_GPIO_PULL_NO;
  GPIO_InitStruct.Alternate = LL_GPIO_AF_5;
  LL_GPIO_Init(SRAM_SPI_MISO_GPIO_Port, &GPIO_InitStruct);

  GPIO_InitStruct.Pin = SRAM_SPI_MOSI_Pin;
  GPIO_InitStruct.Mode = LL_GPIO_MODE_ALTERNATE;
  GPIO_InitStruct.Speed = LL_GPIO_SPEED_FREQ_VERY_HIGH;
  GPIO_InitStruct.OutputType = LL_GPIO_OUTPUT_PUSHPULL;
  GPIO_InitStruct.Pull = LL_GPIO_PULL_NO;
  GPIO_InitStruct.Alternate = LL_GPIO_AF_5;
  LL_GPIO_Init(SRAM_SPI_MOSI_GPIO_Port, &GPIO_InitStruct);

  GPIO_InitStruct.Pin = SRAM_SPI_SCK_Pin;
  GPIO_InitStruct.Mode = LL_GPIO_MODE_ALTERNATE;
  GPIO_InitStruct.Speed = LL_GPIO_SPEED_FREQ_VERY_HIGH;
  GPIO_InitStruct.OutputType = LL_GPIO_OUTPUT_PUSHPULL;
  GPIO_InitStruct.Pull = LL_GPIO_PULL_NO;
  GPIO_InitStruct.Alternate = LL_GPIO_AF_5;
  LL_GPIO_Init(SRAM_SPI_SCK_GPIO_Port, &GPIO_InitStruct);

  /* SPI2 DMA Init */

  /* SPI2_RX Init */
  LL_DMA_SetChannelSelection(DMA1, LL_DMA_STREAM_3, LL_DMA_CHANNEL_0);

  LL_DMA_SetDataTransferDirection(DMA1, LL_DMA_STREAM_3, LL_DMA_DIRECTION_PERIPH_TO_MEMORY);

  LL_DMA_SetStreamPriorityLevel(DMA1, LL_DMA_STREAM_3, LL_DMA_PRIORITY_LOW);

  LL_DMA_SetMode(DMA1, LL_DMA_STREAM_3, LL_DMA_MODE_NORMAL);

  LL_DMA_SetPeriphIncMode(DMA1, LL_DMA_STREAM_3, LL_DMA_PERIPH_NOINCREMENT);

  LL_DMA_SetMemoryIncMode(DMA1, LL_DMA_STREAM_3, LL_DMA_MEMORY_INCREMENT);

  LL_DMA_SetPeriphSize(DMA1, LL_DMA_STREAM_3, LL_DMA_PDATAALIGN_BYTE);

  LL_DMA_SetMemorySize(DMA1, LL_DMA_STREAM_3, LL_DMA_MDATAALIGN_BYTE);

  LL_DMA_DisableFifoMode(DMA1, LL_DMA_STREAM_3);

  /* SPI2_TX Init */
  LL_DMA_SetChannelSelection(DMA1, LL_DMA_STREAM_4, LL_DMA_CHANNEL_0);

  LL_DMA_SetDataTransferDirection(DMA1, LL_DMA_STREAM_4, LL_DMA_DIRECTION_MEMORY_TO_PERIPH);

  LL_DMA_SetStreamPriorityLevel(DMA1, LL_DMA_STREAM_4, LL_DMA_PRIORITY_LOW);

  LL_DMA_SetMode(DMA1, LL_DMA_STREAM_4, LL_DMA_MODE_NORMAL);

  LL_DMA_SetPeriphIncMode(DMA1, LL_DMA_STREAM_4, LL_DMA_PERIPH_NOINCREMENT);

  LL_DMA_SetMemoryIncMode(DMA1, LL_DMA_STREAM_4, LL_DMA_MEMORY_INCREMENT);

  LL_DMA_SetPeriphSize(DMA1, LL_DMA_STREAM_4, LL_DMA_PDATAALIGN_BYTE);

  LL_DMA_SetMemorySize(DMA1, LL_DMA_STREAM_4, LL_DMA_MDATAALIGN_BYTE);

  LL_DMA_DisableFifoMode(DMA1, LL_DMA_STREAM_4);

  /* SPI2 parameter configuration*/
  SPI_InitStruct.TransferDirection = LL_SPI_FULL_DUPLEX;
  SPI_InitStruct.Mode = LL_SPI_MODE_MASTER;
  SPI_InitStruct.DataWidth = LL_SPI_DATAWIDTH_8BIT;
  SPI_InitStruct.ClockPolarity = LL_SPI_POLARITY_HIGH;
  SPI_InitStruct.ClockPhase = LL_SPI_PHASE_2EDGE;
  SPI_InitStruct.NSS = LL_SPI_NSS_SOFT;
  SPI_InitStruct.BaudRate = LL_SPI_BAUDRATEPRESCALER_DIV4;
  SPI_InitStruct.BitOrder = LL_SPI_MSB_FIRST;
  SPI_InitStruct.CRCCalculation = LL_SPI_CRCCALCULATION_DISABLE;
  SPI_InitStruct.CRCPoly = 7;
  LL_SPI_Init(SPI2, &SPI_InitStruct);
  LL_SPI_SetStandard(SPI2, LL_SPI_PROTOCOL_MOTOROLA);
  LL_SPI_DisableNSSPulseMgt(SPI2);

}

static void MX_SPI3_Init(void)
{

  LL_SPI_InitTypeDef SPI_InitStruct = {0};

  LL_GPIO_InitTypeDef GPIO_InitStruct = {0};

  /* Peripheral clock enable */
  LL_APB1_GRP1_EnableClock(LL_APB1_GRP1_PERIPH_SPI3);

  LL_AHB1_GRP1_EnableClock(LL_AHB1_GRP1_PERIPH_GPIOC);
  /**SPI3 GPIO Configuration
  PC10   ------> SPI3_SCK
  PC12   ------> SPI3_MOSI
  */
  GPIO_InitStruct.Pin = UNUSED_SPI_SCK_Pin;
  GPIO_InitStruct.Mode = LL_GPIO_MODE_ALTERNATE;
  GPIO_InitStruct.Speed = LL_GPIO_SPEED_FREQ_VERY_HIGH;
  GPIO_InitStruct.OutputType = LL_GPIO_OUTPUT_PUSHPULL;
  GPIO_InitStruct.Pull = LL_GPIO_PULL_NO;
  GPIO_InitStruct.Alternate = LL_GPIO_AF_6;
  LL_GPIO_Init(UNUSED_SPI_SCK_GPIO_Port, &GPIO_InitStruct);

  GPIO_InitStruct.Pin = NEOPIXEL_DT_Pin;
  GPIO_InitStruct.Mode = LL_GPIO_MODE_ALTERNATE;
  GPIO_InitStruct.Speed = LL_GPIO_SPEED_FREQ_VERY_HIGH;
  GPIO_InitStruct.OutputType = LL_GPIO_OUTPUT_PUSHPULL;
  GPIO_InitStruct.Pull = LL_GPIO_PULL_NO;
  GPIO_InitStruct.Alternate = LL_GPIO_AF_6;
  LL_GPIO_Init(NEOPIXEL_DT_GPIO_Port, &GPIO_InitStruct);

  /* SPI3 DMA Init */

  /* SPI3_TX Init */
  LL_DMA_SetChannelSelection(DMA1, LL_DMA_STREAM_5, LL_DMA_CHANNEL_0);

  LL_DMA_SetDataTransferDirection(DMA1, LL_DMA_STREAM_5, LL_DMA_DIRECTION_MEMORY_TO_PERIPH);

  LL_DMA_SetStreamPriorityLevel(DMA1, LL_DMA_STREAM_5, LL_DMA_PRIORITY_LOW);

  LL_DMA_SetMode(DMA1, LL_DMA_STREAM_5, LL_DMA_MODE_NORMAL);

  LL_DMA_SetPeriphIncMode(DMA1, LL_DMA_STREAM_5, LL_DMA_PERIPH_NOINCREMENT);

  LL_DMA_SetMemoryIncMode(DMA1, LL_DMA_STREAM_5, LL_DMA_MEMORY_INCREMENT);

  LL_DMA_SetPeriphSize(DMA1, LL_DMA_STREAM_5, LL_DMA_PDATAALIGN_HALFWORD);

  LL_DMA_SetMemorySize(DMA1, LL_DMA_STREAM_5, LL_DMA_MDATAALIGN_HALFWORD);

  LL_DMA_DisableFifoMode(DMA1, LL_DMA_STREAM_5);

  /* SPI3 parameter configuration*/
  SPI_InitStruct.TransferDirection = LL_SPI_FULL_DUPLEX;
  SPI_InitStruct.Mode = LL_SPI_MODE_MASTER;
  SPI_InitStruct.DataWidth = LL_SPI_DATAWIDTH_8BIT;
  SPI_InitStruct.ClockPolarity = LL_SPI_POLARITY_HIGH;
  SPI_InitStruct.ClockPhase = LL_SPI_PHASE_2EDGE;
  SPI_InitStruct.NSS = LL_SPI_NSS_SOFT;
  SPI_InitStruct.BaudRate = LL_SPI_BAUDRATEPRESCALER_DIV8;
  SPI_InitStruct.BitOrder = LL_SPI_MSB_FIRST;
  SPI_InitStruct.CRCCalculation = LL_SPI_CRCCALCULATION_DISABLE;
  SPI_InitStruct.CRCPoly = 7;
  LL_SPI_Init(SPI3, &SPI_InitStruct);
  LL_SPI_SetStandard(SPI3, LL_SPI_PROTOCOL_MOTOROLA);
  LL_SPI_DisableNSSPulseMgt(SPI3);

}

static void MX_SPI4_Init(void)
{

  LL_SPI_InitTypeDef SPI_InitStruct = {0};

  LL_GPIO_InitTypeDef GPIO_InitStruct = {0};

  /* Peripheral clock enable */
  LL_APB2_GRP1_EnableClock(LL_APB2_GRP1_PERIPH_SPI4);

  LL_AHB1_GRP1_EnableClock(LL_AHB1_GRP1_PERIPH_GPIOE);
  /**SPI4 GPIO Configuration
  PE6   ------> SPI4_MOSI
  PE12   ------> SPI4_SCK
  PE13   ------> SPI4_MISO
  */
  GPIO_InitStruct.Pin = RPI_SPI_MOSI_Pin;
  GPIO_InitStruct.Mode = LL_GPIO_MODE_ALTERNATE;
  GPIO_InitStruct.Speed = LL_GPIO_SPEED_FREQ_VERY_HIGH;
  GPIO_InitStruct.OutputType = LL_GPIO_OUTPUT_PUSHPULL;
  GPIO_InitStruct.Pull = LL_GPIO_PULL_NO;
  GPIO_InitStruct.Alternate = LL_GPIO_AF_5;
  LL_GPIO_Init(RPI_SPI_MOSI_GPIO_Port, &GPIO_InitStruct);

  GPIO_InitStruct.Pin = RPI_SPI_SCK_Pin;
  GPIO_InitStruct.Mode = LL_GPIO_MODE_ALTERNATE;
  GPIO_InitStruct.Speed = LL_GPIO_SPEED_FREQ_VERY_HIGH;
  GPIO_InitStruct.OutputType = LL_GPIO_OUTPUT_PUSHPULL;
  GPIO_InitStruct.Pull = LL_GPIO_PULL_NO;
  GPIO_InitStruct.Alternate = LL_GPIO_AF_5;
  LL_GPIO_Init(RPI_SPI_SCK_GPIO_Port, &GPIO_InitStruct);

  GPIO_InitStruct.Pin = RPI_SPI_MISO_Pin;
  GPIO_InitStruct.Mode = LL_GPIO_MODE_ALTERNATE;
  GPIO_InitStruct.Speed = LL_GPIO_SPEED_FREQ_VERY_HIGH;
  GPIO_InitStruct.OutputType = LL_GPIO_OUTPUT_PUSHPULL;
  GPIO_InitStruct.Pull = LL_GPIO_PULL_NO;
  GPIO_InitStruct.Alternate = LL_GPIO_AF_5;
  LL_GPIO_Init(RPI_SPI_MISO_GPIO_Port, &GPIO_InitStruct);

  /* SPI4 DMA Init */

  /* SPI4_RX Init */
  LL_DMA_SetChannelSelection(DMA2, LL_DMA_STREAM_0, LL_DMA_CHANNEL_4);

  LL_DMA_SetDataTransferDirection(DMA2, LL_DMA_STREAM_0, LL_DMA_DIRECTION_PERIPH_TO_MEMORY);

  LL_DMA_SetStreamPriorityLevel(DMA2, LL_DMA_STREAM_0, LL_DMA_PRIORITY_LOW);

  LL_DMA_SetMode(DMA2, LL_DMA_STREAM_0, LL_DMA_MODE_NORMAL);

  LL_DMA_SetPeriphIncMode(DMA2, LL_DMA_STREAM_0, LL_DMA_PERIPH_NOINCREMENT);

  LL_DMA_SetMemoryIncMode(DMA2, LL_DMA_STREAM_0, LL_DMA_MEMORY_INCREMENT);

  LL_DMA_SetPeriphSize(DMA2, LL_DMA_STREAM_0, LL_DMA_PDATAALIGN_HALFWORD);

  LL_DMA_SetMemorySize(DMA2, LL_DMA_STREAM_0, LL_DMA_MDATAALIGN_HALFWORD);

  LL_DMA_DisableFifoMode(DMA2, LL_DMA_STREAM_0);

  /* SPI4_TX Init */
  LL_DMA_SetChannelSelection(DMA2, LL_DMA_STREAM_1, LL_DMA_CHANNEL_4);

  LL_DMA_SetDataTransferDirection(DMA2, LL_DMA_STREAM_1, LL_DMA_DIRECTION_MEMORY_TO_PERIPH);

  LL_DMA_SetStreamPriorityLevel(DMA2, LL_DMA_STREAM_1, LL_DMA_PRIORITY_LOW);

  LL_DMA_SetMode(DMA2, LL_DMA_STREAM_1, LL_DMA_MODE_NORMAL);

  LL_DMA_SetPeriphIncMode(DMA2, LL_DMA_STREAM_1, LL_DMA_PERIPH_NOINCREMENT);

  LL_DMA_SetMemoryIncMode(DMA2, LL_DMA_STREAM_1, LL_DMA_MEMORY_INCREMENT);

  LL_DMA_SetPeriphSize(DMA2, LL_DMA_STREAM_1, LL_DMA_PDATAALIGN_HALFWORD);

  LL_DMA_SetMemorySize(DMA2, LL_DMA_STREAM_1, LL_DMA_MDATAALIGN_HALFWORD);

  LL_DMA_DisableFifoMode(DMA2, LL_DMA_STREAM_1);

  /* SPI4 parameter configuration*/
  SPI_InitStruct.TransferDirection = LL_SPI_FULL_DUPLEX;
  SPI_InitStruct.Mode = LL_SPI_MODE_SLAVE;
  SPI_InitStruct.DataWidth = LL_SPI_DATAWIDTH_8BIT;
  SPI_InitStruct.ClockPolarity = LL_SPI_POLARITY_LOW;
  SPI_InitStruct.ClockPhase = LL_SPI_PHASE_2EDGE;
  SPI_InitStruct.NSS = LL_SPI_NSS_SOFT;
  SPI_InitStruct.BitOrder = LL_SPI_MSB_FIRST;
  SPI_InitStruct.CRCCalculation = LL_SPI_CRCCALCULATION_DISABLE;
  SPI_InitStruct.CRCPoly = 7;
  LL_SPI_Init(SPI4, &SPI_InitStruct);
  LL_SPI_SetStandard(SPI4, LL_SPI_PROTOCOL_MOTOROLA);
  LL_SPI_DisableNSSPulseMgt(SPI4);

}

static void MX_TIM6_Init(void)
{

  LL_TIM_InitTypeDef TIM_InitStruct = {0};

  /* Peripheral clock enable */
  LL_APB1_GRP1_EnableClock(LL_APB1_GRP1_PERIPH_TIM6);

  /* TIM6 interrupt Init */
  NVIC_SetPriority(TIM6_DAC_IRQn, NVIC_EncodePriority(NVIC_GetPriorityGrouping(),5, 0));
  NVIC_EnableIRQ(TIM6_DAC_IRQn);

  TIM_InitStruct.Prescaler = 10799;
  TIM_InitStruct.CounterMode = LL_TIM_COUNTERMODE_UP;
  TIM_InitStruct.Autoreload = 4999;
  LL_TIM_Init(TIM6, &TIM_InitStruct);
  LL_TIM_DisableARRPreload(TIM6);
  LL_TIM_SetTriggerOutput(TIM6, LL_TIM_TRGO_RESET);
  LL_TIM_DisableMasterSlaveMode(TIM6);
  /* USER CODE BEGIN TIM6_Init 2 */
  LL_TIM_EnableCounter(TIM6);
  LL_TIM_EnableIT_UPDATE(TIM6);
  /* USER CODE END TIM6_Init 2 */

}

static void MX_TIM10_Init(void)
{

  LL_TIM_InitTypeDef TIM_InitStruct = {0};

  /* Peripheral clock enable */
  LL_APB2_GRP1_EnableClock(LL_APB2_GRP1_PERIPH_TIM10);

  /* TIM10 interrupt Init */
  NVIC_SetPriority(TIM1_UP_TIM10_IRQn, NVIC_EncodePriority(NVIC_GetPriorityGrouping(),5, 0));
  NVIC_EnableIRQ(TIM1_UP_TIM10_IRQn);

  TIM_InitStruct.Prescaler = 10799;
  TIM_InitStruct.CounterMode = LL_TIM_COUNTERMODE_UP;
  TIM_InitStruct.Autoreload = 999;
  TIM_InitStruct.ClockDivision = LL_TIM_CLOCKDIVISION_DIV2;
  LL_TIM_Init(TIM10, &TIM_InitStruct);
  LL_TIM_DisableARRPreload(TIM10);

}

static void MX_USART1_UART_Init(void)
{

  LL_USART_InitTypeDef USART_InitStruct = {0};

  LL_GPIO_InitTypeDef GPIO_InitStruct = {0};

  LL_RCC_SetUSARTClockSource(LL_RCC_USART1_CLKSOURCE_PCLK2);

  /* Peripheral clock enable */
  LL_APB2_GRP1_EnableClock(LL_APB2_GRP1_PERIPH_USART1);

  LL_AHB1_GRP1_EnableClock(LL_AHB1_GRP1_PERIPH_GPIOA);
  LL_AHB1_GRP1_EnableClock(LL_AHB1_GRP1_PERIPH_GPIOB);
  /**USART1 GPIO Configuration
  PA9   ------> USART1_TX
  PB7   ------> USART1_RX
  */
  GPIO_InitStruct.Pin = RPI_UART_TX_Pin;
  GPIO_InitStruct.Mode = LL_GPIO_MODE_ALTERNATE;
  GPIO_InitStruct.Speed = LL_GPIO_SPEED_FREQ_VERY_HIGH;
  GPIO_InitStruct.OutputType = LL_GPIO_OUTPUT_PUSHPULL;
  GPIO_InitStruct.Pull = LL_GPIO_PULL_NO;
  GPIO_InitStruct.Alternate = LL_GPIO_AF_7;
  LL_GPIO_Init(RPI_UART_TX_GPIO_Port, &GPIO_InitStruct);

  GPIO_InitStruct.Pin = RPI_UART_RX_Pin;
  GPIO_InitStruct.Mode = LL_GPIO_MODE_ALTERNATE;
  GPIO_InitStruct.Speed = LL_GPIO_SPEED_FREQ_VERY_HIGH;
  GPIO_InitStruct.OutputType = LL_GPIO_OUTPUT_PUSHPULL;
  GPIO_InitStruct.Pull = LL_GPIO_PULL_NO;
  GPIO_InitStruct.Alternate = LL_GPIO_AF_7;
  LL_GPIO_Init(RPI_UART_RX_GPIO_Port, &GPIO_InitStruct);

  /* USART1 DMA Init */

  /* USART1_TX Init */
  LL_DMA_SetChannelSelection(DMA2, LL_DMA_STREAM_7, LL_DMA_CHANNEL_4);

  LL_DMA_SetDataTransferDirection(DMA2, LL_DMA_STREAM_7, LL_DMA_DIRECTION_MEMORY_TO_PERIPH);

  LL_DMA_SetStreamPriorityLevel(DMA2, LL_DMA_STREAM_7, LL_DMA_PRIORITY_LOW);

  LL_DMA_SetMode(DMA2, LL_DMA_STREAM_7, LL_DMA_MODE_NORMAL);

  LL_DMA_SetPeriphIncMode(DMA2, LL_DMA_STREAM_7, LL_DMA_PERIPH_NOINCREMENT);

  LL_DMA_SetMemoryIncMode(DMA2, LL_DMA_STREAM_7, LL_DMA_MEMORY_INCREMENT);

  LL_DMA_SetPeriphSize(DMA2, LL_DMA_STREAM_7, LL_DMA_PDATAALIGN_BYTE);

  LL_DMA_SetMemorySize(DMA2, LL_DMA_STREAM_7, LL_DMA_MDATAALIGN_BYTE);

  LL_DMA_DisableFifoMode(DMA2, LL_DMA_STREAM_7);

  /* USART1 interrupt Init */
  NVIC_SetPriority(USART1_IRQn, NVIC_EncodePriority(NVIC_GetPriorityGrouping(),5, 0));
  NVIC_EnableIRQ(USART1_IRQn);

  USART_InitStruct.BaudRate = 115200;
  USART_InitStruct.DataWidth = LL_USART_DATAWIDTH_8B;
  USART_InitStruct.StopBits = LL_USART_STOPBITS_1;
  USART_InitStruct.Parity = LL_USART_PARITY_NONE;
  USART_InitStruct.TransferDirection = LL_USART_DIRECTION_TX_RX;
  USART_InitStruct.HardwareFlowControl = LL_USART_HWCONTROL_NONE;
  USART_InitStruct.OverSampling = LL_USART_OVERSAMPLING_16;
  LL_USART_Init(USART1, &USART_InitStruct);
  LL_USART_ConfigAsyncMode(USART1);
  LL_USART_Enable(USART1);

}

static void MX_USART2_UART_Init(void)
{

  LL_USART_InitTypeDef USART_InitStruct = {0};

  LL_GPIO_InitTypeDef GPIO_InitStruct = {0};

  LL_RCC_SetUSARTClockSource(LL_RCC_USART2_CLKSOURCE_PCLK1);

  /* Peripheral clock enable */
  LL_APB1_GRP1_EnableClock(LL_APB1_GRP1_PERIPH_USART2);

  LL_AHB1_GRP1_EnableClock(LL_AHB1_GRP1_PERIPH_GPIOD);
  /**USART2 GPIO Configuration
  PD5   ------> USART2_TX
  PD6   ------> USART2_RX
  */
  GPIO_InitStruct.Pin = IR_UART_TX_Pin;
  GPIO_InitStruct.Mode = LL_GPIO_MODE_ALTERNATE;
  GPIO_InitStruct.Speed = LL_GPIO_SPEED_FREQ_VERY_HIGH;
  GPIO_InitStruct.OutputType = LL_GPIO_OUTPUT_PUSHPULL;
  GPIO_InitStruct.Pull = LL_GPIO_PULL_NO;
  GPIO_InitStruct.Alternate = LL_GPIO_AF_7;
  LL_GPIO_Init(IR_UART_TX_GPIO_Port, &GPIO_InitStruct);

  GPIO_InitStruct.Pin = IR_UART_RX_Pin;
  GPIO_InitStruct.Mode = LL_GPIO_MODE_ALTERNATE;
  GPIO_InitStruct.Speed = LL_GPIO_SPEED_FREQ_VERY_HIGH;
  GPIO_InitStruct.OutputType = LL_GPIO_OUTPUT_PUSHPULL;
  GPIO_InitStruct.Pull = LL_GPIO_PULL_NO;
  GPIO_InitStruct.Alternate = LL_GPIO_AF_7;
  LL_GPIO_Init(IR_UART_RX_GPIO_Port, &GPIO_InitStruct);

  /* USART2 DMA Init */

  /* USART2_TX Init */
  LL_DMA_SetChannelSelection(DMA1, LL_DMA_STREAM_6, LL_DMA_CHANNEL_4);

  LL_DMA_SetDataTransferDirection(DMA1, LL_DMA_STREAM_6, LL_DMA_DIRECTION_MEMORY_TO_PERIPH);

  LL_DMA_SetStreamPriorityLevel(DMA1, LL_DMA_STREAM_6, LL_DMA_PRIORITY_LOW);

  LL_DMA_SetMode(DMA1, LL_DMA_STREAM_6, LL_DMA_MODE_NORMAL);

  LL_DMA_SetPeriphIncMode(DMA1, LL_DMA_STREAM_6, LL_DMA_PERIPH_NOINCREMENT);

  LL_DMA_SetMemoryIncMode(DMA1, LL_DMA_STREAM_6, LL_DMA_MEMORY_INCREMENT);

  LL_DMA_SetPeriphSize(DMA1, LL_DMA_STREAM_6, LL_DMA_PDATAALIGN_BYTE);

  LL_DMA_SetMemorySize(DMA1, LL_DMA_STREAM_6, LL_DMA_MDATAALIGN_BYTE);

  LL_DMA_DisableFifoMode(DMA1, LL_DMA_STREAM_6);

  /* USART2 interrupt Init */
  NVIC_SetPriority(USART2_IRQn, NVIC_EncodePriority(NVIC_GetPriorityGrouping(),5, 0));
  NVIC_EnableIRQ(USART2_IRQn);

  USART_InitStruct.BaudRate = 115200;
  USART_InitStruct.DataWidth = LL_USART_DATAWIDTH_8B;
  USART_InitStruct.StopBits = LL_USART_STOPBITS_1;
  USART_InitStruct.Parity = LL_USART_PARITY_NONE;
  USART_InitStruct.TransferDirection = LL_USART_DIRECTION_TX_RX;
  USART_InitStruct.HardwareFlowControl = LL_USART_HWCONTROL_NONE;
  USART_InitStruct.OverSampling = LL_USART_OVERSAMPLING_16;
  LL_USART_Init(USART2, &USART_InitStruct);
  LL_USART_ConfigAsyncMode(USART2);
  LL_USART_Enable(USART2);

}

static void MX_DMA_Init(void)
{

  /* Init with LL driver */
  /* DMA controller clock enable */
  LL_AHB1_GRP1_EnableClock(LL_AHB1_GRP1_PERIPH_DMA2);
  LL_AHB1_GRP1_EnableClock(LL_AHB1_GRP1_PERIPH_DMA1);

  /* DMA interrupt init */
  /* DMA1_Stream0_IRQn interrupt configuration */
  NVIC_SetPriority(DMA1_Stream0_IRQn, NVIC_EncodePriority(NVIC_GetPriorityGrouping(),5, 0));
  NVIC_EnableIRQ(DMA1_Stream0_IRQn);
  /* DMA1_Stream3_IRQn interrupt configuration */
  NVIC_SetPriority(DMA1_Stream3_IRQn, NVIC_EncodePriority(NVIC_GetPriorityGrouping(),5, 0));
  NVIC_EnableIRQ(DMA1_Stream3_IRQn);
  /* DMA1_Stream4_IRQn interrupt configuration */
  NVIC_SetPriority(DMA1_Stream4_IRQn, NVIC_EncodePriority(NVIC_GetPriorityGrouping(),5, 0));
  NVIC_EnableIRQ(DMA1_Stream4_IRQn);
  /* DMA1_Stream5_IRQn interrupt configuration */
  NVIC_SetPriority(DMA1_Stream5_IRQn, NVIC_EncodePriority(NVIC_GetPriorityGrouping(),5, 0));
  NVIC_EnableIRQ(DMA1_Stream5_IRQn);
  /* DMA1_Stream6_IRQn interrupt configuration */
  NVIC_SetPriority(DMA1_Stream6_IRQn, NVIC_EncodePriority(NVIC_GetPriorityGrouping(),5, 0));
  NVIC_EnableIRQ(DMA1_Stream6_IRQn);
  /* DMA1_Stream7_IRQn interrupt configuration */
  NVIC_SetPriority(DMA1_Stream7_IRQn, NVIC_EncodePriority(NVIC_GetPriorityGrouping(),5, 0));
  NVIC_EnableIRQ(DMA1_Stream7_IRQn);
  /* DMA2_Stream0_IRQn interrupt configuration */
  NVIC_SetPriority(DMA2_Stream0_IRQn, NVIC_EncodePriority(NVIC_GetPriorityGrouping(),5, 0));
  NVIC_EnableIRQ(DMA2_Stream0_IRQn);
  /* DMA2_Stream1_IRQn interrupt configuration */
  NVIC_SetPriority(DMA2_Stream1_IRQn, NVIC_EncodePriority(NVIC_GetPriorityGrouping(),5, 0));
  NVIC_EnableIRQ(DMA2_Stream1_IRQn);
  /* DMA2_Stream3_IRQn interrupt configuration */
  HAL_NVIC_SetPriority(DMA2_Stream3_IRQn, 5, 0);
  HAL_NVIC_EnableIRQ(DMA2_Stream3_IRQn);
  /* DMA2_Stream4_IRQn interrupt configuration */
  NVIC_SetPriority(DMA2_Stream4_IRQn, NVIC_EncodePriority(NVIC_GetPriorityGrouping(),5, 0));
  NVIC_EnableIRQ(DMA2_Stream4_IRQn);
  /* DMA2_Stream5_IRQn interrupt configuration */
  HAL_NVIC_SetPriority(DMA2_Stream5_IRQn, 5, 0);
  HAL_NVIC_EnableIRQ(DMA2_Stream5_IRQn);
  /* DMA2_Stream7_IRQn interrupt configuration */
  NVIC_SetPriority(DMA2_Stream7_IRQn, NVIC_EncodePriority(NVIC_GetPriorityGrouping(),5, 0));
  NVIC_EnableIRQ(DMA2_Stream7_IRQn);

}

static void MX_GPIO_Init(void)
{
  LL_EXTI_InitTypeDef EXTI_InitStruct = {0};
  LL_GPIO_InitTypeDef GPIO_InitStruct = {0};

  /* GPIO Ports Clock Enable */
  LL_AHB1_GRP1_EnableClock(LL_AHB1_GRP1_PERIPH_GPIOE);
  LL_AHB1_GRP1_EnableClock(LL_AHB1_GRP1_PERIPH_GPIOH);
  LL_AHB1_GRP1_EnableClock(LL_AHB1_GRP1_PERIPH_GPIOC);
  LL_AHB1_GRP1_EnableClock(LL_AHB1_GRP1_PERIPH_GPIOA);
  LL_AHB1_GRP1_EnableClock(LL_AHB1_GRP1_PERIPH_GPIOB);
  LL_AHB1_GRP1_EnableClock(LL_AHB1_GRP1_PERIPH_GPIOD);

  /**/
  LL_GPIO_ResetOutputPin(TP13_GPIO_Port, TP13_Pin);

  /**/
  LL_GPIO_ResetOutputPin(TP14_GPIO_Port, TP14_Pin);

  /**/
  LL_GPIO_ResetOutputPin(SRAM_SPI_NSS_GPIO_Port, SRAM_SPI_NSS_Pin);

  /**/
  LL_GPIO_ResetOutputPin(LED_ACT_GPIO_Port, LED_ACT_Pin);

  /**/
  LL_GPIO_ResetOutputPin(PCM_RST_GPIO_Port, PCM_RST_Pin);

  /**/
  GPIO_InitStruct.Pin = TP13_Pin;
  GPIO_InitStruct.Mode = LL_GPIO_MODE_OUTPUT;
  GPIO_InitStruct.Speed = LL_GPIO_SPEED_FREQ_LOW;
  GPIO_InitStruct.OutputType = LL_GPIO_OUTPUT_PUSHPULL;
  GPIO_InitStruct.Pull = LL_GPIO_PULL_NO;
  LL_GPIO_Init(TP13_GPIO_Port, &GPIO_InitStruct);

  /**/
  GPIO_InitStruct.Pin = TP14_Pin;
  GPIO_InitStruct.Mode = LL_GPIO_MODE_OUTPUT;
  GPIO_InitStruct.Speed = LL_GPIO_SPEED_FREQ_LOW;
  GPIO_InitStruct.OutputType = LL_GPIO_OUTPUT_PUSHPULL;
  GPIO_InitStruct.Pull = LL_GPIO_PULL_NO;
  LL_GPIO_Init(TP14_GPIO_Port, &GPIO_InitStruct);

  /**/
  GPIO_InitStruct.Pin = SRAM_SPI_NSS_Pin;
  GPIO_InitStruct.Mode = LL_GPIO_MODE_OUTPUT;
  GPIO_InitStruct.Speed = LL_GPIO_SPEED_FREQ_LOW;
  GPIO_InitStruct.OutputType = LL_GPIO_OUTPUT_PUSHPULL;
  GPIO_InitStruct.Pull = LL_GPIO_PULL_NO;
  LL_GPIO_Init(SRAM_SPI_NSS_GPIO_Port, &GPIO_InitStruct);

  /**/
  GPIO_InitStruct.Pin = LED_ACT_Pin;
  GPIO_InitStruct.Mode = LL_GPIO_MODE_OUTPUT;
  GPIO_InitStruct.Speed = LL_GPIO_SPEED_FREQ_LOW;
  GPIO_InitStruct.OutputType = LL_GPIO_OUTPUT_PUSHPULL;
  GPIO_InitStruct.Pull = LL_GPIO_PULL_NO;
  LL_GPIO_Init(LED_ACT_GPIO_Port, &GPIO_InitStruct);

  /**/
  GPIO_InitStruct.Pin = PCM_RST_Pin;
  GPIO_InitStruct.Mode = LL_GPIO_MODE_OUTPUT;
  GPIO_InitStruct.Speed = LL_GPIO_SPEED_FREQ_LOW;
  GPIO_InitStruct.OutputType = LL_GPIO_OUTPUT_PUSHPULL;
  GPIO_InitStruct.Pull = LL_GPIO_PULL_NO;
  LL_GPIO_Init(PCM_RST_GPIO_Port, &GPIO_InitStruct);

  /**/
  LL_SYSCFG_SetEXTISource(LL_SYSCFG_EXTI_PORTA, LL_SYSCFG_EXTI_LINE5);

  /**/
  LL_SYSCFG_SetEXTISource(LL_SYSCFG_EXTI_PORTA, LL_SYSCFG_EXTI_LINE6);

  /**/
  LL_SYSCFG_SetEXTISource(LL_SYSCFG_EXTI_PORTA, LL_SYSCFG_EXTI_LINE7);

  /**/
  LL_SYSCFG_SetEXTISource(LL_SYSCFG_EXTI_PORTE, LL_SYSCFG_EXTI_LINE11);

  /**/
  EXTI_InitStruct.Line_0_31 = LL_EXTI_LINE_5;
  EXTI_InitStruct.LineCommand = ENABLE;
  EXTI_InitStruct.Mode = LL_EXTI_MODE_IT;
  EXTI_InitStruct.Trigger = LL_EXTI_TRIGGER_FALLING;
  LL_EXTI_Init(&EXTI_InitStruct);

  /**/
  EXTI_InitStruct.Line_0_31 = LL_EXTI_LINE_6;
  EXTI_InitStruct.LineCommand = ENABLE;
  EXTI_InitStruct.Mode = LL_EXTI_MODE_IT;
  EXTI_InitStruct.Trigger = LL_EXTI_TRIGGER_FALLING;
  LL_EXTI_Init(&EXTI_InitStruct);

  /**/
  EXTI_InitStruct.Line_0_31 = LL_EXTI_LINE_7;
  EXTI_InitStruct.LineCommand = ENABLE;
  EXTI_InitStruct.Mode = LL_EXTI_MODE_IT;
  EXTI_InitStruct.Trigger = LL_EXTI_TRIGGER_FALLING;
  LL_EXTI_Init(&EXTI_InitStruct);

  /**/
  EXTI_InitStruct.Line_0_31 = LL_EXTI_LINE_11;
  EXTI_InitStruct.LineCommand = ENABLE;
  EXTI_InitStruct.Mode = LL_EXTI_MODE_IT;
  EXTI_InitStruct.Trigger = LL_EXTI_TRIGGER_FALLING;
  LL_EXTI_Init(&EXTI_InitStruct);

  /**/
  LL_GPIO_SetPinPull(GPIO_IN_INT_SW2_N_GPIO_Port, GPIO_IN_INT_SW2_N_Pin, LL_GPIO_PULL_UP);

  /**/
  LL_GPIO_SetPinPull(GPIO_IN_INT_MPU_N_GPIO_Port, GPIO_IN_INT_MPU_N_Pin, LL_GPIO_PULL_UP);

  /**/
  LL_GPIO_SetPinPull(GPIO_IN_INT_SW_N_GPIO_Port, GPIO_IN_INT_SW_N_Pin, LL_GPIO_PULL_UP);

  /**/
  LL_GPIO_SetPinPull(RPI_SPI_NSS_GPIO_Port, RPI_SPI_NSS_Pin, LL_GPIO_PULL_NO);

  /**/
  LL_GPIO_SetPinMode(GPIO_IN_INT_SW2_N_GPIO_Port, GPIO_IN_INT_SW2_N_Pin, LL_GPIO_MODE_INPUT);

  /**/
  LL_GPIO_SetPinMode(GPIO_IN_INT_MPU_N_GPIO_Port, GPIO_IN_INT_MPU_N_Pin, LL_GPIO_MODE_INPUT);

  /**/
  LL_GPIO_SetPinMode(GPIO_IN_INT_SW_N_GPIO_Port, GPIO_IN_INT_SW_N_Pin, LL_GPIO_MODE_INPUT);

  /**/
  LL_GPIO_SetPinMode(RPI_SPI_NSS_GPIO_Port, RPI_SPI_NSS_Pin, LL_GPIO_MODE_INPUT);

  /* EXTI interrupt init*/
  NVIC_SetPriority(EXTI9_5_IRQn, NVIC_EncodePriority(NVIC_GetPriorityGrouping(),5, 0));
  NVIC_EnableIRQ(EXTI9_5_IRQn);
  NVIC_SetPriority(EXTI15_10_IRQn, NVIC_EncodePriority(NVIC_GetPriorityGrouping(),5, 0));
  NVIC_EnableIRQ(EXTI15_10_IRQn);

}

__weak void usbTxTaskProc(void const * argument)
{
  /* init code for USB_DEVICE */
  MX_USB_DEVICE_Init();
  for(;;)
  {
    osDelay(1);
  }
}

void HAL_TIM_PeriodElapsedCallback(TIM_HandleTypeDef *htim)
{
  if (htim->Instance == TIM7) {
    HAL_IncTick();
  }
}

void Error_Handler(void)
{
  __disable_irq();
  while (1)
  {
  }
}
